# nrf5340 register map
Vendor: Nordic Semiconductor; Series: nrf53; File version: 1
CPU: CM33 r0p2, little endian, MPU, FPU, 3 interrupt priority bits
Registers are 32-bit, read-write, reset 0x0 unless marked. A register's access mark holds for its fields unless they carry their own. Offsets are from the block's base; [hi:lo] are bit positions; lines under a group give offsets from that group; {n}, {i} and the like mark numbered series; 'fields as' and 'values as' point back to an identical list.

## DCNF_NS — Domain Configuration Management 0
Base 0x40000000; alternate view of AMLI_NS
Same registers: DCNF_S 0x50000000 (alternate view of AMLI_S)
0x100 EVENTS_FPUIOC — Invalid Operation exception.
  [0] EVENTS_FPUIOC
    0=NotGenerated (Event not generated); 1=Generated (Event generated)
0x104 EVENTS_FPUDZC — Division by Zero exception.
  [0] EVENTS_FPUDZC
    values as EVENTS_FPUIOC.EVENTS_FPUIOC
0x108 EVENTS_FPUOFC — Overflow exception.
  [0] EVENTS_FPUOFC
    values as EVENTS_FPUIOC.EVENTS_FPUIOC
0x10C EVENTS_FPUUFC — Underflow exception.
  [0] EVENTS_FPUUFC
    values as EVENTS_FPUIOC.EVENTS_FPUIOC
0x110 EVENTS_FPUIXC — Inexact exception.
  [0] EVENTS_FPUIXC
    values as EVENTS_FPUIOC.EVENTS_FPUIOC
0x114 EVENTS_FPUIDC — Input Denormal exception.
  [0] EVENTS_FPUIDC
    values as EVENTS_FPUIOC.EVENTS_FPUIOC
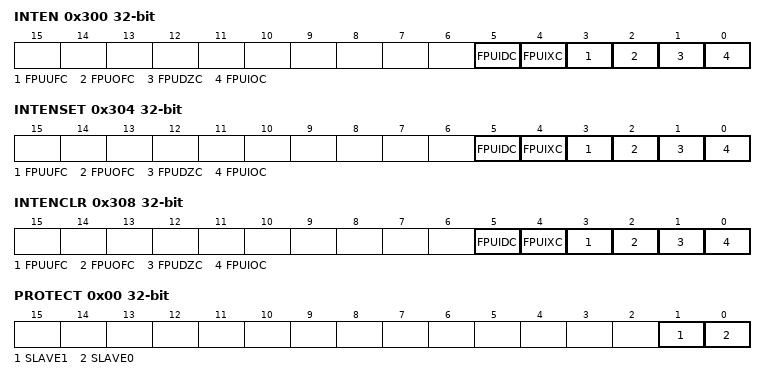
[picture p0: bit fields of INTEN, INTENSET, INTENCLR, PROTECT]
0x300 INTEN — Enable or disable interrupt
  [all] fields
    0=Disabled; 1=Enabled
  [5] FPUIDC — Enable or disable interrupt for event FPUIDC
  [4] FPUIXC — Enable or disable interrupt for event FPUIXC
  [3] FPUUFC — Enable or disable interrupt for event FPUUFC
  [2] FPUOFC — Enable or disable interrupt for event FPUOFC
  [1] FPUDZC — Enable or disable interrupt for event FPUDZC
  [0] FPUIOC — Enable or disable interrupt for event FPUIOC
0x304 INTENSET — Enable interrupt
  [all] fields
    on read: 0=Disabled (Read: Disabled); 1=Enabled (Read: Enabled) | on write: 1=Set (Enable)
  [5] FPUIDC — Write '1' to enable interrupt for event FPUIDC
  [4] FPUIXC — Write '1' to enable interrupt for event FPUIXC
  [3] FPUUFC — Write '1' to enable interrupt for event FPUUFC
  [2] FPUOFC — Write '1' to enable interrupt for event FPUOFC
  [1] FPUDZC — Write '1' to enable interrupt for event FPUDZC
  [0] FPUIOC — Write '1' to enable interrupt for event FPUIOC
0x308 INTENCLR — Disable interrupt
  [all] fields
    on read: 0=Disabled (Read: Disabled); 1=Enabled (Read: Enabled) | on write: 1=Clear (Disable)
  [5] FPUIDC — Write '1' to disable interrupt for event FPUIDC
  [4] FPUIXC — Write '1' to disable interrupt for event FPUIXC
  [3] FPUUFC — Write '1' to disable interrupt for event FPUUFC
  [2] FPUOFC — Write '1' to disable interrupt for event FPUOFC
  [1] FPUDZC — Write '1' to disable interrupt for event FPUDZC
  [0] FPUIOC — Write '1' to disable interrupt for event FPUIOC
0x420 CPUID ro — CPU number in the system
  [7:0] CPUID
{0x440+4i} EXTPERI[{i}] (i=0..0) group — Unspecified
  0x00 PROTECT — Description cluster: Control access for Master connected to AMLI master port EXTPERI[n]
    [2:0] SLAVE — Control access to peripherals from master EXTPERI[n].
      0=Allowed (Access to peripherals is allowed); 7=Blocked (Access to peripherals is blocked)
{0x448+4i} EXTPERI1[{i}] (i=0..5) group — Unspecified
  0x00 UNUSED0 — Unspecified
{0x460+4i} EXTRAM[{i}] (i=0..0) group — Unspecified
  0x00 PROTECT — Description cluster: Control access from Master connected to AMLI master port EXTRAM[n]
    [1] SLAVE1 — Control access to slave 1 of master EXTRAM[n].
      0=Allowed (Access to slave is possible); 1=Blocked (Access to slave is blocked)
    [0] SLAVE0 — Control access to slave 0 of master EXTRAM[n].
      values as SLAVE1
{0x468+4i} EXTRAM1[{i}] (i=0..5) group — Unspecified
  0x00 UNUSED1 — Unspecified
{0x480+4i} EXTCODE[{i}] (i=0..0) group — Unspecified
  0x00 PROTECT — Description cluster: Control access from Master connected to AMLI master port EXTCODE[n]
    [0] SLAVE0 — Control access to slave 0 of master EXTCODE[n].
      values as EXTRAM[0].PROTECT.SLAVE1
{0x488+4i} EXTCODE1[{i}] (i=0..5) group — Unspecified
  0x00 UNUSED2 — Unspecified
0xA00 FPGA group — Only exists on FPGA nightly build
  0x00 SVNREVISION ro
  0x04 OFFICIAL ro — Official release
    [0] OFFICIAL
      0=NotOfficial; 1=Official
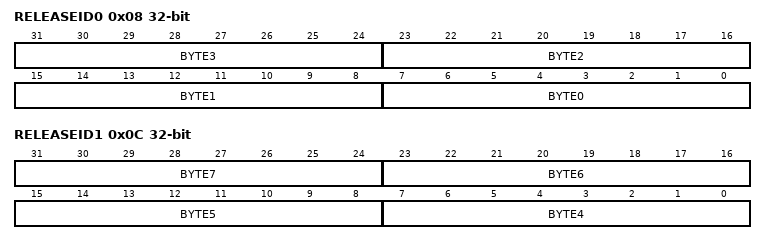
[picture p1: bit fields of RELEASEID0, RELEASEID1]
  0x08 RELEASEID0 ro — Release ID string
    [8n+7:8n] BYTE{n} (n=0..3) — Release ID string byte {n}
  0x0C RELEASEID1 ro — Release ID string
    [8n-25:8n-32] BYTE{n} (n=4..7) — Release ID string byte {n}
  0x10 JOBNUMBER ro — Jenkins job number
0xA20 AMLICLOCKDELAY reset 0x3
  [5:0] AMLICLOCKDELAY
